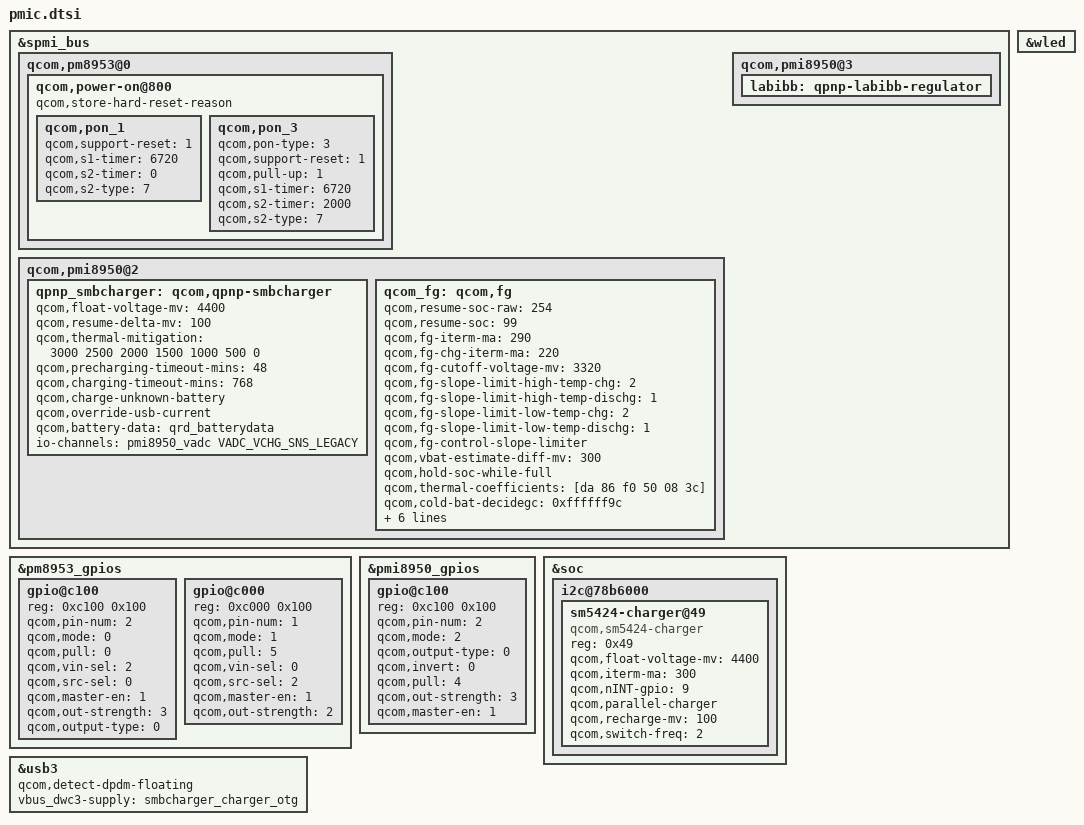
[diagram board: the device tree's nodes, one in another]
/* msm-pm8953 */

#include <dt-bindings/pinctrl/qcom,pmic-gpio.h>

&spmi_bus {
	qcom,pm8953@0 {
		qcom,power-on@800 {
			qcom,store-hard-reset-reason;
			qcom,pon_1 {
				qcom,support-reset = <1>;
				qcom,s1-timer = <6720>;
				qcom,s2-timer = <0>;
				qcom,s2-type = <7>;
			};

			qcom,pon_3 {
				qcom,pon-type = <3>;
				qcom,support-reset = <1>;
				qcom,pull-up = <1>;
				qcom,s1-timer = <6720>;
				qcom,s2-timer = <2000>;
				qcom,s2-type = <7>;
			};
		};
		/delete-node/ qcom,pm8953_typec@bf00;
	};
};

&pm8953_gpios {
    gpio@c100 {
        reg = <0xc100 0x100>;
        qcom,pin-num = <2>;
        qcom,mode = <0>;
        qcom,pull = <0>;
        qcom,vin-sel = <2>;
        qcom,src-sel = <0>;
        qcom,master-en = <1>;
        qcom,out-strength = <3>;
        qcom,output-type = <0>;
        status = "okay";
    };
    
    gpio@c000 {
        reg = <0xc000 0x100>;
        qcom,pin-num = <1>;
        qcom,mode = <1>;
        qcom,pull = <5>;
        qcom,vin-sel = <0>;
        qcom,src-sel = <2>;
        qcom,master-en = <1>;
        qcom,out-strength = <2>;
        status = "okay";
    };
};

&pmi8950_gpios {
    gpio@c100 {
        reg = <0xc100 0x100>;
        qcom,pin-num = <2>;
        qcom,mode = <2>;
        qcom,output-type = <0>;
        qcom,invert = <0>;
        qcom,pull = <4>;
        qcom,out-strength = <3>;
        qcom,master-en = <1>;
        status = "okay";
    };
};

&soc {
	i2c@78b6000 {
        status = "ok";

        sm5424-charger@49 {
            compatible = "qcom,sm5424-charger";
            reg = <0x49>;
            status = "ok";
            
            qcom,float-voltage-mv = <4400>;
            qcom,iterm-ma = <300>;
            qcom,nINT-gpio = <9>;
            qcom,parallel-charger;
            qcom,recharge-mv = <100>;
            qcom,switch-freq = <2>;
        };
    };
};

/* msm-pmi8950 */
&spmi_bus {
	qcom,pmi8950@2 {
		qpnp_smbcharger: qcom,qpnp-smbcharger {
			qcom,float-voltage-mv = <4400>;
			qcom,resume-delta-mv = <100>;
			qcom,thermal-mitigation = <3000 2500 2000 1500 1000 500 0>;
			qcom,precharging-timeout-mins = <48>;
			qcom,charging-timeout-mins = <768>;
			qcom,charge-unknown-battery;
			qcom,override-usb-current;
			qcom,battery-data = <&qrd_batterydata>;
			io-channels = <&pmi8950_vadc VADC_VCHG_SNS_LEGACY>;
			io-channel-names = "vchg_sns";

			/delete-property/ qcom,autoadjust-vfloat;
			/delete-property/ qcom,external-typec;
			/delete-property/ qcom,typec-psy-name;
		};

		qcom_fg: qcom,fg {
			qcom,resume-soc-raw = <254>;
			qcom,resume-soc = <99>;
			qcom,fg-iterm-ma = <290>;
			qcom,fg-chg-iterm-ma = <220>;
			qcom,fg-cutoff-voltage-mv = <3320>;
			qcom,fg-slope-limit-high-temp-chg = <2>;
			qcom,fg-slope-limit-high-temp-dischg = <1>;
			qcom,fg-slope-limit-low-temp-chg = <2>;
			qcom,fg-slope-limit-low-temp-dischg = <1>;
			qcom,fg-control-slope-limiter;
			qcom,vbat-estimate-diff-mv = <300>;
			qcom,hold-soc-while-full;
			qcom,thermal-coefficients = [da 86 f0 50 08 3c];
			qcom,cold-bat-decidegc = <0xffffff9c>; /* -99 */
			qcom,cool-bat-decidegc = <0>;
			qcom,warm-bat-decidegc = <550>;
			qcom,hot-bat-decidegc = <550>;
			qcom,bad-battery-detection-enable;
			qcom,ext-sense-type;
			qcom,battery-data = <&qrd_batterydata>;
		};
	};
};

&usb3 {
	qcom,detect-dpdm-floating;
	vbus_dwc3-supply = <&smbcharger_charger_otg>;
};

&spmi_bus {
	qcom,pmi8950@3 {
		labibb: qpnp-labibb-regulator {
			status = "ok";
		};
	};
};

&wled {
	/delete-property/ qcom,en-ext-pfet-sc-pro;
};
